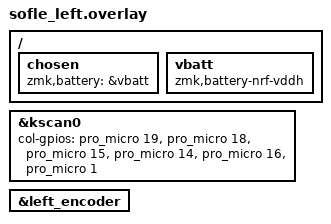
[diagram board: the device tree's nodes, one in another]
/*
 * Copyright (c) 2020 Ryan Cross
 *
 * SPDX-License-Identifier: MIT
 */

#include "sofle.dtsi"

&kscan0 {
    col-gpios
        = <&pro_micro 19 (GPIO_ACTIVE_HIGH | GPIO_PULL_DOWN)>
        , <&pro_micro 18 (GPIO_ACTIVE_HIGH | GPIO_PULL_DOWN)>
        , <&pro_micro 15 (GPIO_ACTIVE_HIGH | GPIO_PULL_DOWN)>
        , <&pro_micro 14 (GPIO_ACTIVE_HIGH | GPIO_PULL_DOWN)>
        , <&pro_micro 16 (GPIO_ACTIVE_HIGH | GPIO_PULL_DOWN)>
        , <&pro_micro 1 (GPIO_ACTIVE_HIGH | GPIO_PULL_DOWN)>
        ;
};

&left_encoder {
    status = "okay";
};
/ {
    chosen {
      zmk,battery = &vbatt;
    };

    vbatt: vbatt {
        compatible = "zmk,battery-nrf-vddh";
    };
};
